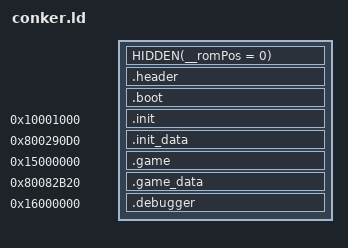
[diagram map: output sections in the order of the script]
SECTIONS
{
    HIDDEN(__romPos = 0);
    header_ROM_START = __romPos;
    header_VRAM = ADDR(.header);
    .header : AT(header_ROM_START) SUBALIGN(16)
    {
        FILL(0x00000000);
        header_DATA_START = .;
        build/asm/header.s.o(.data);
        header_DATA_END = .;
        header_DATA_SIZE = ABSOLUTE(header_DATA_END - header_DATA_START);
    }
    __romPos += SIZEOF(.header);
    header_ROM_END = __romPos;
    header_VRAM_END = .;

    boot_ROM_START = __romPos;
    boot_VRAM = ADDR(.boot);
    .boot : AT(boot_ROM_START) SUBALIGN(16)
    {
        FILL(0x00000000);
        boot_DATA_START = .;
        build/assets/boot.bin.o(.data);
        boot_DATA_END = .;
        boot_DATA_SIZE = ABSOLUTE(boot_DATA_END - boot_DATA_START);
    }
    __romPos += SIZEOF(.boot);
    boot_ROM_END = __romPos;
    boot_VRAM_END = .;

    init_ROM_START = __romPos;
    init_VRAM = ADDR(.init);
    .init 0x10001000 : AT(init_ROM_START) SUBALIGN(16)
    {
        FILL(0x00000000);
        init_TEXT_START = .;
        build/asm/entrypoint.s.o(.text);
        build/src/init_1050.c.o(.text);
        build/src/init_1420.c.o(.text);
        build/src/init_2070.c.o(.text);
        build/src/libultra/io/aisetnextbuf.c.o(.text);
        build/src/init_2E50.c.o(.text);
        build/src/libultra/io/pimgr.c.o(.text);
        build/src/libultra/io/sptask.c.o(.text);
        build/asm/libultra/io/vimgr.s.o(.text);
        build/src/libultra/os/createthread.c.o(.text);
        build/src/init_38C0.c.o(.text);
        build/src/init_38E0.c.o(.text);
        build/src/init_3920.c.o(.text);
        build/src/init_3930.c.o(.text);
        build/src/init_39B0.c.o(.text);
        build/src/init_39C0.c.o(.text);
        build/src/init_3BD0.c.o(.text);
        build/src/init_3C40.c.o(.text);
        build/src/init_4470.c.o(.text);
        build/src/init_49E0.c.o(.text);
        build/src/init_50A0.c.o(.text);
        build/asm/libultra/io/motor.s.o(.text);
        build/asm/init_5AB0.s.o(.text);
        build/asm/libultra/os/maptlbrdb.s.o(.text);
        build/src/init_8180.c.o(.text);
        build/src/init_8F90.c.o(.text);
        build/src/init_A420.c.o(.text);
        build/src/init_B1B0.c.o(.text);
        build/src/init_EB00.c.o(.text);
        build/src/init_11FA0.c.o(.text);
        build/src/init_12560.c.o(.text);
        build/src/libultra/audio/heap.c.o(.text);
        build/src/libultra/audio/init_128D0.c.o(.text);
        build/src/libultra/audio/n_csplayer.c.o(.text);
        build/src/libultra/audio/init_15550.c.o(.text);
        build/src/libultra/audio/init_17870.c.o(.text);
        build/src/libultra/audio/n_cspgetstate.c.o(.text);
        build/src/libultra/audio/code_17AA0.c.o(.text);
        build/src/libultra/audio/init_17AF0.c.o(.text);
        build/src/libultra/audio/init_17C00.c.o(.text);
        build/src/libultra/audio/code_17D80.c.o(.text);
        build/src/libultra/audio/init_17DF0.c.o(.text);
        build/src/libultra/audio/n_cspgettempo.c.o(.text);
        build/src/libultra/audio/init_17F10.c.o(.text);
        build/src/libultra/audio/n_csq.c.o(.text);
        build/src/libultra/audio/code_18C60.c.o(.text);
        build/src/libultra/audio/code_18CB0.c.o(.text);
        build/src/libultra/audio/init_18D00.c.o(.text);
        build/src/libultra/audio/init_18D50.c.o(.text);
        build/src/libultra/audio/n_sl.c.o(.text);
        build/src/libultra/audio/n_synthesizer.c.o(.text);
        build/src/libultra/audio/cents2ratio.c.o(.text);
        build/src/libultra/audio/init_19B50.c.o(.text);
        build/src/init_1AAE0.c.o(.text);
        build/src/init_1C060.c.o(.text);
        build/src/libultra/audio/n_synaddplayer.c.o(.text);
        build/src/libultra/audio/n_synstopvoice.c.o(.text);
        build/src/libultra/audio/n_synfreevoice.c.o(.text);
        build/src/libultra/audio/n_synsetvol.c.o(.text);
        build/src/libultra/audio/n_synsetpitch.c.o(.text);
        build/src/libultra/audio/n_synsetpitch2.c.o(.text);
        build/src/libultra/audio/n_synsetpan.c.o(.text);
        build/src/libultra/audio/init_1CBF0.c.o(.text);
        build/src/libultra/audio/init_1D900.c.o(.text);
        build/src/libultra/audio/n_cseqnextdelta.c.o(.text);
        build/src/libultra/audio/n_synallocvoice.c.o(.text);
        build/src/libultra/audio/n_synstartvoiceparam.c.o(.text);
        build/src/libultra/audio/init_1E2A0.c.o(.text);
        build/src/libultra/audio/init_1E350.c.o(.text);
        build/src/libultra/audio/init_1E400.c.o(.text);
        build/src/init_1E480.c.o(.text);
        build/src/init_1E4A0.c.o(.text);
        build/src/init_1E530.c.o(.text);
        build/src/init_1FB40.c.o(.text);
        build/src/libultra/audio/n_synsetpriority.c.o(.text);
        build/src/init_20000.c.o(.text);
        build/src/init_210C0.c.o(.text);
        build/src/init_214F0.c.o(.text);
        build/src/init_22040.c.o(.text);
        build/src/init_22460.c.o(.text);
        build/asm/libultra/libc/bzero.s.o(.text);
        build/src/libultra/os/initialize.c.o(.text);
        build/asm/libultra/os/setsr.s.o(.text);
        build/asm/libultra/os/getsr.s.o(.text);
        build/asm/libultra/os/setfpccsr.s.o(.text);
        build/asm/libultra/os/startthread.s.o(.text);
        build/asm/libultra/os/setthreadpri.s.o(.text);
        build/asm/libultra/os/invalicache.s.o(.text);
        build/asm/libultra/os/invaldcache.s.o(.text);
        build/asm/libultra/os/interrupt.s.o(.text);
        build/asm/libultra/os/stopthread.s.o(.text);
        build/asm/libultra/libc/string.s.o(.text);
        build/asm/libultra/libc/lldiv.s.o(.text);
        build/asm/libultra/libc/ldiv.s.o(.text);
        build/asm/libultra/libc/xlitob.s.o(.text);
        build/src/libultra/io/ai.c.o(.text);
        build/asm/libultra/os/virtualtophysical.s.o(.text);
        build/asm/libultra/os/recvmesg.s.o(.text);
        build/asm/libultra/os/sendmesg.s.o(.text);
        build/asm/libultra/os/piacs.s.o(.text);
        build/asm/libultra/os/createmesgqueue.s.o(.text);
        build/asm/libultra/os/seteventmesg.s.o(.text);
        build/src/libultra/os/getthreadpri.c.o(.text);
        build/asm/libultra/io/pirawdma.s.o(.text);
        build/asm/libultra/io/epirawdma.s.o(.text);
        build/asm/libultra/libc/bcopy.s.o(.text);
        build/asm/libultra/os/writebackdcache.s.o(.text);
        build/asm/libultra/io/spsetstat.s.o(.text);
        build/asm/libultra/io/spsetpc.s.o(.text);
        build/asm/libultra/io/sprawdma.s.o(.text);
        build/asm/libultra/io/sp.s.o(.text);
        build/asm/libultra/os/timerintr.s.o(.text);
        build/asm/libultra/io/vi.s.o(.text);
        build/asm/libultra/io/pigettype.s.o(.text);
        build/asm/libultra/io/viswapcontext.s.o(.text);
        build/asm/libultra/os/getcount.s.o(.text);
        build/asm/libultra/os/thread.s.o(.text);
        build/asm/libultra/io/visetmode.s.o(.text);
        build/asm/libultra/io/viswapbuf.s.o(.text);
        build/asm/libultra/os/setintmask.s.o(.text);
        build/asm/libultra/io/pidma.s.o(.text);
        build/src/libultra/io/aigetstat.c.o(.text);
        build/asm/libultra/os/settimer.s.o(.text);
        build/asm/libultra/io/sptaskyielded.s.o(.text);
        build/asm/libultra/io/sptaskyield.s.o(.text);
        build/asm/libultra/io/contreaddata.s.o(.text);
        build/asm/libultra/io/vigetcurrframebuf.s.o(.text);
        build/asm/libultra/io/vigetnextframebuf.s.o(.text);
        build/asm/libultra/io/visetevent.s.o(.text);
        build/asm/libultra/os/writebackdcacheall.s.o(.text);
        build/asm/libultra/os/gettime.s.o(.text);
        build/asm/libultra/io/pfsisplug.s.o(.text);
        build/asm/libultra/io/controller.s.o(.text);
        build/asm/libultra/io/siacs.s.o(.text);
        build/asm/libultra/io/sirawdma.s.o(.text);
        build/asm/libultra/io/contramwrite.s.o(.text);
        build/asm/libultra/io/contramread.s.o(.text);
        build/asm/libultra/io/crc.s.o(.text);
        build/asm/libultra/os/destroythread.s.o(.text);
        build/asm/libultra/io/viblack.s.o(.text);
        build/asm/libultra/io/pigetstat.s.o(.text);
        build/asm/libultra/os/unmaptlb.s.o(.text);
        build/asm/libultra/os/maptlb.s.o(.text);
        build/src/libultra/io/aisetfreq.c.o(.text);
        build/asm/libultra/gu/sqrtf.s.o(.text);
        build/asm/libultra/gu/sinf.s.o(.text);
        build/asm/libultra/io/sprawread.s.o(.text);
        build/asm/libultra/io/sprawwrite.s.o(.text);
        build/asm/libultra/io/pirawread.s.o(.text);
        build/asm/libultra/libc/__ull_rshift.s.o(.text);
        build/asm/libultra/os/sethwinterrupt.s.o(.text);
        build/asm/libultra/io/leointerrupt.s.o(.text);
        build/asm/libultra/os/probetlb.s.o(.text);
        build/asm/libultra/os/setcompare.s.o(.text);
        build/asm/libultra/os/jammesg.s.o(.text);
        build/asm/libultra/io/pigetcmdq.s.o(.text);
        build/asm/libultra/io/spgetstat.s.o(.text);
        build/asm/libultra/io/si.s.o(.text);
        build/asm/libultra/io/pfsinit.s.o(.text);
        build/asm/libultra/io/leodiskinit.s.o(.text);
        build/asm/libultra/io/contpfs.s.o(.text);
        build/asm/libultra/io/pfschecker.s.o(.text);
        . = ALIGN(., 16);
        init_TEXT_END = .;
        init_TEXT_SIZE = ABSOLUTE(init_TEXT_END - init_TEXT_START);
    }
    __romPos += SIZEOF(.init);
    __romPos = ALIGN(__romPos, 16);
    . = ALIGN(., 16);
    init_ROM_END = __romPos;
    init_VRAM_END = .;

    init_data_ROM_START = __romPos;
    init_data_VRAM = ADDR(.init_data);
    .init_data 0x800290D0 : AT(init_data_ROM_START) SUBALIGN(16)
    {
        FILL(0x00000000);
        init_data_DATA_START = .;
        build/asm/data/290D0.data.s.o(.data);
        . = ALIGN(., 16);
        init_data_DATA_END = .;
        init_data_DATA_SIZE = ABSOLUTE(init_data_DATA_END - init_data_DATA_START);
        init_data_RODATA_START = .;
        build/asm/data/2BF20.rodata.s.o(.rodata);
        build/asm/data/2C080.rodata.s.o(.rodata);
        build/asm/data/2C0A0.rodata.s.o(.rodata);
        build/asm/data/2C0C0.rodata.s.o(.rodata);
        build/asm/data/2C120.rodata.s.o(.rodata);
        build/asm/data/2C1B0.rodata.s.o(.rodata);
        build/asm/data/2C200.rodata.s.o(.rodata);
        build/asm/data/2C240.rodata.s.o(.rodata);
        build/asm/data/2C250.rodata.s.o(.rodata);
        build/src/libultra/audio/init_128D0.c.o(.rodata);
        build/asm/data/2C460.rodata.s.o(.rodata);
        build/asm/data/2C6B0.rodata.s.o(.rodata);
        build/asm/data/2C750.rodata.s.o(.rodata);
        build/src/libultra/audio/cents2ratio.c.o(.rodata);
        build/asm/data/2C770.rodata.s.o(.rodata);
        build/src/libultra/audio/init_1D900.c.o(.rodata);
        build/asm/data/2C7A0.rodata.s.o(.rodata);
        build/asm/data/2C820.rodata.s.o(.rodata);
        build/asm/data/2C830.rodata.s.o(.rodata);
        build/asm/data/2C850.rodata.s.o(.rodata);
        build/asm/data/2C920.rodata.s.o(.rodata);
        build/asm/data/2C960.rodata.s.o(.rodata);
        . = ALIGN(., 16);
        init_data_RODATA_END = .;
        init_data_RODATA_SIZE = ABSOLUTE(init_data_RODATA_END - init_data_RODATA_START);
    }
    __romPos += SIZEOF(.init_data);
    __romPos = ALIGN(__romPos, 16);
    . = ALIGN(., 16);
    init_data_ROM_END = __romPos;
    init_data_VRAM_END = .;

    game_ROM_START = __romPos;
    game_VRAM = ADDR(.game);
    .game 0x15000000 : AT(game_ROM_START) SUBALIGN(16)
    {
        FILL(0x00000000);
        game_TEXT_START = .;
        build/src/game_2D4B0.c.o(.text);
        build/src/game_2DDF0.c.o(.text);
        build/src/game_2DF70.c.o(.text);
        build/src/game_305D0.c.o(.text);
        build/src/game_30E90.c.o(.text);
        build/src/game_32200.c.o(.text);
        build/src/game/done/game_322B0.c.o(.text);
        build/src/game/done/game_323B0.c.o(.text);
        build/src/game/done/game_323E0.c.o(.text);
        build/src/game_32490.c.o(.text);
        build/src/game/done/game_32720.c.o(.text);
        build/src/game_32740.c.o(.text);
        build/src/game/done/game_32F10.c.o(.text);
        build/src/game/done/game_32F60.c.o(.text);
        build/src/game/done/game_32FB0.c.o(.text);
        build/src/game/done/game_32FC0.c.o(.text);
        build/src/game/done/game_33000.c.o(.text);
        build/src/game/done/game_33010.c.o(.text);
        build/src/game/done/game_33020.c.o(.text);
        build/src/game/done/game_33080.c.o(.text);
        build/src/game/done/game_330E0.c.o(.text);
        build/src/game/done/game_33130.c.o(.text);
        build/src/game/done/game_331B0.c.o(.text);
        build/src/game/done/game_33210.c.o(.text);
        build/src/game/done/game_33260.c.o(.text);
        build/src/game/done/game_332E0.c.o(.text);
        build/src/game/done/game_33320.c.o(.text);
        build/src/game/done/game_33390.c.o(.text);
        build/src/game/done/game_333D0.c.o(.text);
        build/src/game/done/game_33410.c.o(.text);
        build/src/game/done/game_33450.c.o(.text);
        build/src/game/done/game_33460.c.o(.text);
        build/src/game/done/game_334C0.c.o(.text);
        build/src/game/done/game_33620.c.o(.text);
        build/src/game_33660.c.o(.text);
        build/src/game_33990.c.o(.text);
        build/src/game/entrypoint.c.o(.text);
        build/src/game/done/game_34ED0.c.o(.text);
        build/src/game_34F20.c.o(.text);
        build/src/game_357F0.c.o(.text);
        build/src/game/done/game_35CF0.c.o(.text);
        build/src/game_35D20.c.o(.text);
        build/src/game/done/game_35E80.c.o(.text);
        build/src/game/done/game_35EC0.c.o(.text);
        build/src/game/done/game_36040.c.o(.text);
        build/src/game_360A0.c.o(.text);
        build/src/game/done/game_36280.c.o(.text);
        build/src/game_362B0.c.o(.text);
        build/src/game/done/game_36600.c.o(.text);
        build/src/game_36680.c.o(.text);
        build/src/game/done/game_39690.c.o(.text);
        build/src/game_39750.c.o(.text);
        build/src/game_3B920.c.o(.text);
        build/src/game_3BA70.c.o(.text);
        build/src/game/done/game_3BFD0.c.o(.text);
        build/src/game/done/game_3BFE0.c.o(.text);
        build/src/game/done/game_3C230.c.o(.text);
        build/src/game/done/game_3C3D0.c.o(.text);
        build/src/game/done/game_3C6C0.c.o(.text);
        build/asm/3C740.s.o(.text);
        build/asm/3CE80.s.o(.text);
        build/asm/3D2E0.s.o(.text);
        build/src/game_3D5C0.c.o(.text);
        build/src/game/done/game_3D6F0.c.o(.text);
        build/src/game/done/game_3D770.c.o(.text);
        build/src/game/done/game_3D780.c.o(.text);
        build/src/game_3D9A0.c.o(.text);
        build/src/game/done/game_3DB30.c.o(.text);
        build/src/game/done/game_3DB50.c.o(.text);
        build/src/game/done/game_3DB60.c.o(.text);
        build/src/game/done/game_3DB80.c.o(.text);
        build/src/game_3DC30.c.o(.text);
        build/src/game_3DF10.c.o(.text);
        build/src/game/done/game_3E460.c.o(.text);
        build/src/game/done/game_3E5A0.c.o(.text);
        build/src/game/done/game_3E620.c.o(.text);
        build/src/game/done/game_3E7E0.c.o(.text);
        build/src/game/done/game_3E810.c.o(.text);
        build/src/game_3E890.c.o(.text);
        build/src/game/done/game_3EFB0.c.o(.text);
        build/src/game/done/game_3F0F0.c.o(.text);
        build/src/game/done/game_3F120.c.o(.text);
        build/src/game_3F1F0.c.o(.text);
        build/src/game/done/game_3F3D0.c.o(.text);
        build/src/game/done/game_3F450.c.o(.text);
        build/src/game/done/game_3F4D0.c.o(.text);
        build/src/game/done/game_3F560.c.o(.text);
        build/src/game_3F670.c.o(.text);
        build/src/game_3F820.c.o(.text);
        build/src/game/done/game_3FBD0.c.o(.text);
        build/src/game/done/game_3FC20.c.o(.text);
        build/src/game/done/game_3FC30.c.o(.text);
        build/asm/3FC60.s.o(.text);
        build/src/game_40490.c.o(.text);
        build/asm/42DC0.s.o(.text);
        build/asm/43330.s.o(.text);
        build/src/game_433F0.c.o(.text);
        build/src/game_43620.c.o(.text);
        build/src/game/done/game_43760.c.o(.text);
        build/src/game/done/game_43820.c.o(.text);
        build/asm/43880.s.o(.text);
        build/src/game_439B0.c.o(.text);
        build/src/game/done/game_43B20.c.o(.text);
        build/asm/43D00.s.o(.text);
        build/src/game_447B0.c.o(.text);
        build/src/game_44A90.c.o(.text);
        build/src/game_44C40.c.o(.text);
        build/asm/45880.s.o(.text);
        build/src/game_45B80.c.o(.text);
        build/src/game_476D0.c.o(.text);
        build/asm/487D0.s.o(.text);
        build/asm/48FD0.s.o(.text);
        build/asm/49BE0.s.o(.text);
        build/src/game/done/game_49D10.c.o(.text);
        build/src/game/done/game_49D20.c.o(.text);
        build/asm/49D30.s.o(.text);
        build/asm/50D20.s.o(.text);
        build/asm/50D80.s.o(.text);
        build/src/game_57FA0.c.o(.text);
        build/asm/58F80.s.o(.text);
        build/asm/5D2C0.s.o(.text);
        build/asm/61490.s.o(.text);
        build/asm/61D10.s.o(.text);
        build/asm/637C0.s.o(.text);
        build/asm/63A20.s.o(.text);
        build/asm/64120.s.o(.text);
        build/asm/68C70.s.o(.text);
        build/asm/6A3D0.s.o(.text);
        build/asm/6B280.s.o(.text);
        build/asm/6B320.s.o(.text);
        build/asm/6C960.s.o(.text);
        build/asm/6CCB0.s.o(.text);
        build/asm/6CEA0.s.o(.text);
        build/src/game_6D800.c.o(.text);
        build/src/game_6E240.c.o(.text);
        build/asm/6E770.s.o(.text);
        build/src/game_70200.c.o(.text);
        build/src/game_71240.c.o(.text);
        build/src/game_71770.c.o(.text);
        build/asm/71820.s.o(.text);
        build/src/libultra/gu/cosf.c.o(.text);
        build/src/libultra/gu/sinf.c.o(.text);
        build/src/libultra/gu/guPerspectiveF.c.o(.text);
        build/src/libultra/gu/guRotateF.c.o(.text);
        build/src/game/done/game_75810.c.o(.text);
        build/src/game/done/game_75950.c.o(.text);
        build/src/game/done/game_75A90.c.o(.text);
        build/src/game/done/game_75BD0.c.o(.text);
        build/src/game_75C90.c.o(.text);
        build/src/game_75E60.c.o(.text);
        build/src/game_75FC0.c.o(.text);
        build/src/game_76710.c.o(.text);
        build/src/game/done/game_768F0.c.o(.text);
        build/asm/76A60.s.o(.text);
        build/asm/76C90.s.o(.text);
        build/asm/76E50.s.o(.text);
        build/asm/770F0.s.o(.text);
        build/asm/77760.s.o(.text);
        build/asm/778B0.s.o(.text);
        build/src/game/done/game_77A90.c.o(.text);
        build/src/game_77AD0.c.o(.text);
        build/src/game_83300.c.o(.text);
        build/asm/90840.s.o(.text);
        build/asm/97AA0.s.o(.text);
        build/src/game_981E0.c.o(.text);
        build/src/game_A28B0.c.o(.text);
        build/asm/A9260.s.o(.text);
        build/src/game_A9D90.c.o(.text);
        build/asm/AB760.s.o(.text);
        build/asm/AC030.s.o(.text);
        build/asm/AD6B0.s.o(.text);
        build/asm/AD9B0.s.o(.text);
        build/asm/AE1D0.s.o(.text);
        build/asm/AEB40.s.o(.text);
        build/asm/B21B0.s.o(.text);
        build/asm/B3020.s.o(.text);
        build/src/game_BC430.c.o(.text);
        build/src/game_BC510.c.o(.text);
        build/asm/C1D70.s.o(.text);
        build/asm/C3E20.s.o(.text);
        build/asm/C4DC0.s.o(.text);
        build/src/game_C8950.c.o(.text);
        build/asm/C98F0.s.o(.text);
        build/asm/C9EC0.s.o(.text);
        build/src/game_CB1C0.c.o(.text);
        build/asm/CB3D0.s.o(.text);
        build/asm/CBAF0.s.o(.text);
        build/asm/CBDB0.s.o(.text);
        build/asm/CCD00.s.o(.text);
        build/asm/CD5A0.s.o(.text);
        build/asm/CD860.s.o(.text);
        build/asm/CDE80.s.o(.text);
        build/asm/D0F20.s.o(.text);
        build/asm/D2570.s.o(.text);
        build/asm/D3040.s.o(.text);
        build/asm/D3D10.s.o(.text);
        build/asm/D4450.s.o(.text);
        build/src/game_D4C20.c.o(.text);
        build/src/libultra/gu/guMtxF2L.c.o(.text);
        build/asm/D4E10.s.o(.text);
        build/src/game_D5030.c.o(.text);
        build/src/libultra/gu/guMtxIdentF.c.o(.text);
        build/asm/D50C0.s.o(.text);
        build/src/game_D5160.c.o(.text);
        build/src/game_D51B0.c.o(.text);
        build/src/game_D5250.c.o(.text);
        build/asm/D52A0.s.o(.text);
        build/src/game_D5500.c.o(.text);
        build/asm/D5650.s.o(.text);
        build/asm/D70F0.s.o(.text);
        build/asm/D7980.s.o(.text);
        build/asm/D86A0.s.o(.text);
        build/asm/DAC20.s.o(.text);
        build/asm/DAC30.s.o(.text);
        build/asm/DAD60.s.o(.text);
        build/asm/DADB0.s.o(.text);
        build/asm/DAE10.s.o(.text);
        build/src/game_DAE50.c.o(.text);
        build/asm/DAFA0.s.o(.text);
        build/src/game_DBA60.c.o(.text);
        build/asm/DC360.s.o(.text);
        build/asm/DC6B0.s.o(.text);
        build/asm/DDB60.s.o(.text);
        build/asm/DE5A0.s.o(.text);
        build/asm/DF260.s.o(.text);
        build/asm/DF930.s.o(.text);
        build/asm/DFBF0.s.o(.text);
        build/asm/E0F60.s.o(.text);
        build/asm/E1280.s.o(.text);
        build/asm/E2880.s.o(.text);
        build/asm/E2DA0.s.o(.text);
        build/asm/E3C90.s.o(.text);
        build/asm/E4070.s.o(.text);
        build/asm/E5E90.s.o(.text);
        build/asm/E7380.s.o(.text);
        build/asm/E7970.s.o(.text);
        build/asm/E8090.s.o(.text);
        build/asm/E8BB0.s.o(.text);
        build/asm/E8C10.s.o(.text);
        build/asm/EB020.s.o(.text);
        build/asm/EB340.s.o(.text);
        build/asm/EBD00.s.o(.text);
        build/asm/EBE60.s.o(.text);
        build/asm/EC420.s.o(.text);
        build/asm/EDE60.s.o(.text);
        build/asm/EE710.s.o(.text);
        build/asm/EEB10.s.o(.text);
        build/asm/EEE70.s.o(.text);
        build/src/game_EF410.c.o(.text);
        build/asm/F15D0.s.o(.text);
        build/src/game/done/game_F20A0.c.o(.text);
        build/asm/F21D0.s.o(.text);
        build/asm/F2820.s.o(.text);
        build/asm/F3270.s.o(.text);
        build/asm/F3BA0.s.o(.text);
        build/asm/F44D0.s.o(.text);
        build/asm/F4800.s.o(.text);
        build/asm/F4890.s.o(.text);
        build/asm/F4B20.s.o(.text);
        build/asm/F4C20.s.o(.text);
        build/asm/F4D20.s.o(.text);
        build/asm/F52B0.s.o(.text);
        build/asm/F5800.s.o(.text);
        build/asm/F8590.s.o(.text);
        build/asm/F9430.s.o(.text);
        build/asm/FA240.s.o(.text);
        build/asm/FA360.s.o(.text);
        build/asm/FB060.s.o(.text);
        build/asm/FB600.s.o(.text);
        build/src/game/done/game_FC3C0.c.o(.text);
        build/asm/FC410.s.o(.text);
        build/asm/FC550.s.o(.text);
        build/asm/FC5F0.s.o(.text);
        build/asm/FDB00.s.o(.text);
        build/asm/FDBE0.s.o(.text);
        build/asm/FDD70.s.o(.text);
        build/asm/FE850.s.o(.text);
        build/asm/FE9E0.s.o(.text);
        build/asm/FECC0.s.o(.text);
        build/asm/FEFF0.s.o(.text);
        build/asm/FF0E0.s.o(.text);
        build/asm/FF5C0.s.o(.text);
        build/asm/FF900.s.o(.text);
        build/asm/FFBA0.s.o(.text);
        build/asm/100810.s.o(.text);
        build/asm/1028F0.s.o(.text);
        build/asm/1045D0.s.o(.text);
        build/asm/1048D0.s.o(.text);
        build/asm/105760.s.o(.text);
        build/asm/105FC0.s.o(.text);
        build/asm/108320.s.o(.text);
        build/asm/108E90.s.o(.text);
        build/src/game/done/game_10B7C0.c.o(.text);
        build/asm/10B7D0.s.o(.text);
        build/src/game/done/game_10C140.c.o(.text);
        build/asm/10C170.s.o(.text);
        build/asm/10CCD0.s.o(.text);
        build/asm/10CD70.s.o(.text);
        build/asm/10DD20.s.o(.text);
        build/asm/10E240.s.o(.text);
        build/asm/10EA20.s.o(.text);
        build/src/game/done/game_10ECB0.c.o(.text);
        build/asm/10ED10.s.o(.text);
        build/asm/10EF60.s.o(.text);
        build/asm/1104D0.s.o(.text);
        build/asm/111670.s.o(.text);
        build/asm/112F90.s.o(.text);
        build/asm/113480.s.o(.text);
        build/asm/113D60.s.o(.text);
        build/asm/116D40.s.o(.text);
        build/asm/117490.s.o(.text);
        build/asm/118400.s.o(.text);
        build/asm/118670.s.o(.text);
        build/asm/1188E0.s.o(.text);
        build/asm/119370.s.o(.text);
        build/src/game/done/game_119960.c.o(.text);
        build/asm/1199D0.s.o(.text);
        build/asm/11A680.s.o(.text);
        build/asm/11C2B0.s.o(.text);
        build/asm/11F780.s.o(.text);
        build/asm/11FF10.s.o(.text);
        build/asm/121A20.s.o(.text);
        build/src/game/done/game_122650.c.o(.text);
        build/asm/122760.s.o(.text);
        build/asm/1227F0.s.o(.text);
        build/asm/1228D0.s.o(.text);
        build/src/game_123FB0.c.o(.text);
        build/asm/124260.s.o(.text);
        build/asm/124920.s.o(.text);
        build/asm/126ED0.s.o(.text);
        build/asm/126F60.s.o(.text);
        build/asm/128970.s.o(.text);
        build/asm/128D70.s.o(.text);
        build/src/game/done/game_129EB0.c.o(.text);
        build/asm/129EE0.s.o(.text);
        build/asm/12B1C0.s.o(.text);
        build/asm/12B250.s.o(.text);
        build/asm/12B7D0.s.o(.text);
        build/asm/12BD10.s.o(.text);
        build/asm/12C1E0.s.o(.text);
        build/asm/12D630.s.o(.text);
        build/src/game/done/game_12D7E0.c.o(.text);
        build/asm/12D7F0.s.o(.text);
        build/asm/12DAB0.s.o(.text);
        build/asm/12FDD0.s.o(.text);
        build/asm/1308E0.s.o(.text);
        build/asm/130B40.s.o(.text);
        build/src/game_130CB0.c.o(.text);
        build/asm/1312F0.s.o(.text);
        build/asm/131620.s.o(.text);
        build/asm/1319D0.s.o(.text);
        build/asm/131A90.s.o(.text);
        build/src/game_131F30.c.o(.text);
        build/asm/133190.s.o(.text);
        build/asm/135490.s.o(.text);
        build/asm/1355D0.s.o(.text);
        build/asm/135780.s.o(.text);
        build/asm/135D00.s.o(.text);
        build/asm/1368C0.s.o(.text);
        build/asm/137DE0.s.o(.text);
        build/asm/137ED0.s.o(.text);
        build/asm/138520.s.o(.text);
        build/asm/139FC0.s.o(.text);
        build/asm/13AE20.s.o(.text);
        build/asm/13BB20.s.o(.text);
        build/asm/13D350.s.o(.text);
        build/asm/142560.s.o(.text);
        build/asm/14CE30.s.o(.text);
        build/src/game/done/game_14D0D0.c.o(.text);
        build/asm/14D110.s.o(.text);
        build/asm/14EE80.s.o(.text);
        build/asm/14F130.s.o(.text);
        build/asm/14F580.s.o(.text);
        build/asm/14F8F0.s.o(.text);
        build/src/game_14FF90.c.o(.text);
        build/asm/155C90.s.o(.text);
        build/asm/156160.s.o(.text);
        build/asm/1570E0.s.o(.text);
        build/asm/157840.s.o(.text);
        build/asm/159940.s.o(.text);
        build/src/game/done/game_15A830.c.o(.text);
        build/asm/15A840.s.o(.text);
        build/asm/15AA10.s.o(.text);
        build/asm/15ABA0.s.o(.text);
        build/src/game_15B200.c.o(.text);
        build/asm/15B5F0.s.o(.text);
        build/asm/15B960.s.o(.text);
        build/asm/15BAA0.s.o(.text);
        build/asm/15BD90.s.o(.text);
        build/asm/15D6E0.s.o(.text);
        build/asm/15D730.s.o(.text);
        build/asm/15F680.s.o(.text);
        build/src/game_161520.c.o(.text);
        build/src/game_168A90.c.o(.text);
        build/src/game_169510.c.o(.text);
        build/src/game_16DC80.c.o(.text);
        build/src/game_16EE20.c.o(.text);
        build/asm/173D40.s.o(.text);
        build/asm/174BF0.s.o(.text);
        build/asm/175250.s.o(.text);
        build/src/game/done/game_1765E0.c.o(.text);
        build/asm/176A00.s.o(.text);
        build/asm/179F30.s.o(.text);
        build/asm/17CAF0.s.o(.text);
        build/asm/182C30.s.o(.text);
        build/asm/183640.s.o(.text);
        build/asm/185560.s.o(.text);
        build/asm/188440.s.o(.text);
        build/asm/188F90.s.o(.text);
        build/src/game_1897A0.c.o(.text);
        build/asm/18A8F0.s.o(.text);
        build/asm/18D250.s.o(.text);
        build/src/game_18D770.c.o(.text);
        build/asm/191C30.s.o(.text);
        build/asm/193130.s.o(.text);
        build/src/game/done/game_193420.c.o(.text);
        build/asm/193430.s.o(.text);
        build/asm/193E50.s.o(.text);
        build/src/game_1944C0.c.o(.text);
        build/asm/196DB0.s.o(.text);
        build/asm/197120.s.o(.text);
        build/asm/197C20.s.o(.text);
        build/asm/19A8B0.s.o(.text);
        build/asm/19E040.s.o(.text);
        build/asm/19F150.s.o(.text);
        build/asm/1A0100.s.o(.text);
        build/asm/1A0420.s.o(.text);
        build/asm/1A0790.s.o(.text);
        build/asm/1A0E60.s.o(.text);
        build/asm/1A11B0.s.o(.text);
        build/asm/1A1B40.s.o(.text);
        build/asm/1A1E50.s.o(.text);
        build/asm/1A20A0.s.o(.text);
        build/asm/1A48C0.s.o(.text);
        build/asm/1A5440.s.o(.text);
        build/src/game/done/game_1A6300.c.o(.text);
        build/asm/1A6360.s.o(.text);
        build/asm/1A7260.s.o(.text);
        build/asm/1A8060.s.o(.text);
        build/asm/1A89B0.s.o(.text);
        build/asm/1AB530.s.o(.text);
        build/asm/1AC2F0.s.o(.text);
        build/asm/1AFC80.s.o(.text);
        build/asm/1B0740.s.o(.text);
        build/asm/1B1600.s.o(.text);
        build/asm/1B5370.s.o(.text);
        build/asm/1B5CC0.s.o(.text);
        build/asm/1B6DB0.s.o(.text);
        build/asm/1B74A0.s.o(.text);
        build/asm/1B7870.s.o(.text);
        build/asm/1B7EC0.s.o(.text);
        build/asm/1B81D0.s.o(.text);
        build/asm/1B8B60.s.o(.text);
        build/asm/1B8F40.s.o(.text);
        build/asm/1B9DB0.s.o(.text);
        build/asm/1B9F30.s.o(.text);
        build/asm/1BA1D0.s.o(.text);
        build/asm/1BF090.s.o(.text);
        build/src/game_1BFC70.c.o(.text);
        build/asm/1BFCB0.s.o(.text);
        build/asm/1BFDD0.s.o(.text);
        build/asm/1C0840.s.o(.text);
        build/asm/1C0B10.s.o(.text);
        build/asm/1C1150.s.o(.text);
        build/asm/1C2C60.s.o(.text);
        build/asm/1CA420.s.o(.text);
        build/asm/1CBE20.s.o(.text);
        build/src/game/done/game_1CC420.c.o(.text);
        build/asm/1CC440.s.o(.text);
        build/asm/1D0840.s.o(.text);
        build/asm/1D2B10.s.o(.text);
        build/asm/1D43B0.s.o(.text);
        build/asm/1D4E00.s.o(.text);
        build/asm/1D6E80.s.o(.text);
        build/asm/1D92F0.s.o(.text);
        build/asm/1DCA70.s.o(.text);
        build/asm/1DD500.s.o(.text);
        build/asm/1DF510.s.o(.text);
        build/asm/1E0560.s.o(.text);
        build/asm/1E2180.s.o(.text);
        build/asm/1E26F0.s.o(.text);
        build/asm/1E3050.s.o(.text);
        build/asm/1E30A0.s.o(.text);
        build/asm/1E34C0.s.o(.text);
        build/asm/1E37D0.s.o(.text);
        build/asm/1E58B0.s.o(.text);
        build/asm/1E5FF0.s.o(.text);
        build/asm/1E6260.s.o(.text);
        build/asm/1E6B40.s.o(.text);
        build/asm/1E73B0.s.o(.text);
        build/asm/1ED0F0.s.o(.text);
        build/asm/1EF500.s.o(.text);
        build/asm/1F2730.s.o(.text);
        build/asm/1F3780.s.o(.text);
        build/asm/1F4650.s.o(.text);
        build/asm/1FA770.s.o(.text);
        build/asm/1FFB70.s.o(.text);
        build/src/game_1FFF60.c.o(.text);
        build/asm/200930.s.o(.text);
        build/asm/203340.s.o(.text);
        build/asm/203E20.s.o(.text);
        build/asm/204660.s.o(.text);
        build/asm/205C90.s.o(.text);
        build/src/game_2062D0.c.o(.text);
        build/asm/209B50.s.o(.text);
        build/asm/20A290.s.o(.text);
        build/asm/20A3A0.s.o(.text);
        build/asm/20A5F0.s.o(.text);
        build/asm/20A850.s.o(.text);
        build/asm/20A910.s.o(.text);
        build/asm/20A990.s.o(.text);
        build/asm/20AE20.s.o(.text);
        build/asm/215960.s.o(.text);
        build/asm/21C4F0.s.o(.text);
        build/asm/21C540.s.o(.text);
        build/asm/libultra/io/pfsinit2.s.o(.text);
        build/asm/21CAC0.s.o(.text);
        build/asm/21CAF0.s.o(.text);
        build/asm/21CCB0.s.o(.text);
        build/asm/21CE70.s.o(.text);
        build/asm/libultra/io/contreaddata2.s.o(.text);
        build/asm/21D1B0.s.o(.text);
        build/asm/21D420.s.o(.text);
        build/src/libultra/gu/guNormalize.c.o(.text);
        build/src/libultra/gu/mtxcatl.c.o(.text);
        build/src/game_21D5F0.c.o(.text);
        build/asm/libultra/io/siacs2.s.o(.text);
        build/asm/libultra/io/sirawdma2.s.o(.text);
        build/asm/libultra/os/gettime2.s.o(.text);
        build/asm/libultra/io/contpfs2.s.o(.text);
        build/src/libultra/io/pfschecker2.c.o(.text);
        build/src/libultra/io/pfsisplug2.c.o(.text);
        build/asm/libultra/io/contramread2.s.o(.text);
        build/asm/libultra/io/contramwrite2.s.o(.text);
        build/src/libultra/audio/game_21FC90.c.o(.text);
        build/src/game_221290.c.o(.text);
        build/asm/225D20.s.o(.text);
        build/asm/2270A0.s.o(.text);
        . = ALIGN(., 16);
        game_TEXT_END = .;
        game_TEXT_SIZE = ABSOLUTE(game_TEXT_END - game_TEXT_START);
    }
    __romPos += SIZEOF(.game);
    __romPos = ALIGN(__romPos, 16);
    . = ALIGN(., 16);
    game_ROM_END = __romPos;
    game_VRAM_END = .;

    game_data_ROM_START = __romPos;
    game_data_VRAM = ADDR(.game_data);
    .game_data 0x80082B20 : AT(game_data_ROM_START) SUBALIGN(16)
    {
        FILL(0x00000000);
        game_data_DATA_START = .;
        build/asm/data/2275E0.data.s.o(.data);
        . = ALIGN(., 16);
        game_data_DATA_END = .;
        game_data_DATA_SIZE = ABSOLUTE(game_data_DATA_END - game_data_DATA_START);
        game_data_RODATA_START = .;
        build/asm/data/22A980.rodata.s.o(.rodata);
        build/asm/data/22AA90.rodata.s.o(.rodata);
        build/asm/data/22AAB0.rodata.s.o(.rodata);
        build/asm/data/22AAC0.rodata.s.o(.rodata);
        build/asm/data/22ABC0.rodata.s.o(.rodata);
        build/asm/data/22ABD0.rodata.s.o(.rodata);
        build/asm/data/22AC10.rodata.s.o(.rodata);
        build/asm/data/22B1F0.rodata.s.o(.rodata);
        build/asm/data/22B560.rodata.s.o(.rodata);
        build/asm/data/22B660.rodata.s.o(.rodata);
        build/asm/data/22B720.rodata.s.o(.rodata);
        build/asm/data/22BD00.rodata.s.o(.rodata);
        build/asm/data/22BD20.rodata.s.o(.rodata);
        build/asm/data/22BD40.rodata.s.o(.rodata);
        build/asm/data/22BD50.rodata.s.o(.rodata);
        build/asm/data/22BD70.rodata.s.o(.rodata);
        build/asm/data/22BD90.rodata.s.o(.rodata);
        build/asm/data/22BDE0.rodata.s.o(.rodata);
        build/asm/data/22BE40.rodata.s.o(.rodata);
        build/asm/data/22BE50.rodata.s.o(.rodata);
        build/asm/data/22BE70.rodata.s.o(.rodata);
        build/asm/data/22BE90.rodata.s.o(.rodata);
        build/asm/data/22BED0.rodata.s.o(.rodata);
        build/asm/data/22BEF0.rodata.s.o(.rodata);
        build/asm/data/22D000.rodata.s.o(.rodata);
        build/asm/data/22D040.rodata.s.o(.rodata);
        build/asm/data/22D070.rodata.s.o(.rodata);
        build/asm/data/22D1A0.rodata.s.o(.rodata);
        build/asm/data/22D1B0.rodata.s.o(.rodata);
        build/asm/data/22D1C0.rodata.s.o(.rodata);
        build/asm/data/22D1D0.rodata.s.o(.rodata);
        build/asm/data/22D1E0.rodata.s.o(.rodata);
        build/asm/data/22D1F0.rodata.s.o(.rodata);
        build/asm/data/22D210.rodata.s.o(.rodata);
        build/asm/data/22D220.rodata.s.o(.rodata);
        build/asm/data/22D250.rodata.s.o(.rodata);
        build/asm/data/22D2A0.rodata.s.o(.rodata);
        build/asm/data/22D2C0.rodata.s.o(.rodata);
        build/asm/data/22D2D0.rodata.s.o(.rodata);
        build/asm/data/22D2E0.rodata.s.o(.rodata);
        build/asm/data/22D330.rodata.s.o(.rodata);
        build/asm/data/22D350.rodata.s.o(.rodata);
        build/asm/data/22D380.rodata.s.o(.rodata);
        build/asm/data/22D3C0.rodata.s.o(.rodata);
        build/asm/data/22D3D0.rodata.s.o(.rodata);
        build/asm/data/22D3F0.rodata.s.o(.rodata);
        build/asm/data/22D400.rodata.s.o(.rodata);
        build/asm/data/22D410.rodata.s.o(.rodata);
        build/asm/data/22D420.rodata.s.o(.rodata);
        build/asm/data/22D440.rodata.s.o(.rodata);
        build/asm/data/22D450.rodata.s.o(.rodata);
        build/asm/data/22D460.rodata.s.o(.rodata);
        build/asm/data/22D480.rodata.s.o(.rodata);
        build/asm/data/22D4D0.rodata.s.o(.rodata);
        build/asm/data/22D4E0.rodata.s.o(.rodata);
        build/asm/data/22D550.rodata.s.o(.rodata);
        build/asm/data/22D560.rodata.s.o(.rodata);
        build/asm/data/22D5C0.rodata.s.o(.rodata);
        build/asm/data/22D5E0.rodata.s.o(.rodata);
        build/asm/data/22D600.rodata.s.o(.rodata);
        build/asm/data/22D610.rodata.s.o(.rodata);
        build/asm/data/22D620.rodata.s.o(.rodata);
        build/asm/data/22D640.rodata.s.o(.rodata);
        build/asm/data/22D650.rodata.s.o(.rodata);
        build/asm/data/22D660.rodata.s.o(.rodata);
        build/asm/data/22D670.rodata.s.o(.rodata);
        build/asm/data/22D680.rodata.s.o(.rodata);
        build/asm/data/22D690.rodata.s.o(.rodata);
        build/asm/data/22D6C0.rodata.s.o(.rodata);
        build/asm/data/22D6D0.rodata.s.o(.rodata);
        build/asm/data/22D710.rodata.s.o(.rodata);
        build/asm/data/22DB80.rodata.s.o(.rodata);
        build/asm/data/22DBE0.rodata.s.o(.rodata);
        build/asm/data/22DBF0.rodata.s.o(.rodata);
        build/asm/data/22DD00.rodata.s.o(.rodata);
        build/asm/data/22DD20.rodata.s.o(.rodata);
        build/asm/data/22DDE0.rodata.s.o(.rodata);
        build/asm/data/22DF30.rodata.s.o(.rodata);
        build/asm/data/22DF70.rodata.s.o(.rodata);
        build/asm/data/22DF80.rodata.s.o(.rodata);
        build/asm/data/22DFA0.rodata.s.o(.rodata);
        build/asm/data/22DFB0.rodata.s.o(.rodata);
        build/asm/data/22DFE0.rodata.s.o(.rodata);
        build/asm/data/22E020.rodata.s.o(.rodata);
        build/asm/data/22E030.rodata.s.o(.rodata);
        build/asm/data/22E040.rodata.s.o(.rodata);
        build/asm/data/22E050.rodata.s.o(.rodata);
        build/asm/data/22E090.rodata.s.o(.rodata);
        build/asm/data/22E0F0.rodata.s.o(.rodata);
        build/asm/data/22E1F0.rodata.s.o(.rodata);
        build/asm/data/22E220.rodata.s.o(.rodata);
        build/asm/data/22E370.rodata.s.o(.rodata);
        build/asm/data/22E4E0.rodata.s.o(.rodata);
        build/asm/data/22E680.rodata.s.o(.rodata);
        build/asm/data/22E730.rodata.s.o(.rodata);
        build/asm/data/22EB40.rodata.s.o(.rodata);
        build/asm/data/22EC20.rodata.s.o(.rodata);
        build/asm/data/22EC90.rodata.s.o(.rodata);
        build/asm/data/22ECB0.rodata.s.o(.rodata);
        build/asm/data/22ECC0.rodata.s.o(.rodata);
        build/asm/data/22EEA0.rodata.s.o(.rodata);
        build/asm/data/22EF30.rodata.s.o(.rodata);
        build/asm/data/22EF80.rodata.s.o(.rodata);
        build/asm/data/22F530.rodata.s.o(.rodata);
        build/asm/data/22F650.rodata.s.o(.rodata);
        build/asm/data/22F720.rodata.s.o(.rodata);
        build/asm/data/22F730.rodata.s.o(.rodata);
        build/asm/data/22F7F0.rodata.s.o(.rodata);
        build/asm/data/22F800.rodata.s.o(.rodata);
        build/asm/data/22F820.rodata.s.o(.rodata);
        build/asm/data/22F840.rodata.s.o(.rodata);
        build/asm/data/22F850.rodata.s.o(.rodata);
        build/asm/data/22F8B0.rodata.s.o(.rodata);
        build/asm/data/22F8C0.rodata.s.o(.rodata);
        build/asm/data/22F920.rodata.s.o(.rodata);
        build/asm/data/22F9A0.rodata.s.o(.rodata);
        build/asm/data/22FA40.rodata.s.o(.rodata);
        build/asm/data/22FA90.rodata.s.o(.rodata);
        build/asm/data/22FB10.rodata.s.o(.rodata);
        build/asm/data/22FB50.rodata.s.o(.rodata);
        build/asm/data/22FB90.rodata.s.o(.rodata);
        build/asm/data/22FE50.rodata.s.o(.rodata);
        build/asm/data/22FE60.rodata.s.o(.rodata);
        build/asm/data/22FEA0.rodata.s.o(.rodata);
        build/asm/data/22FF00.rodata.s.o(.rodata);
        build/asm/data/22FF40.rodata.s.o(.rodata);
        build/asm/data/22FF90.rodata.s.o(.rodata);
        build/asm/data/231650.rodata.s.o(.rodata);
        build/asm/data/231660.rodata.s.o(.rodata);
        build/asm/data/2316E0.rodata.s.o(.rodata);
        build/asm/data/2316F0.rodata.s.o(.rodata);
        build/asm/data/231730.rodata.s.o(.rodata);
        build/asm/data/231850.rodata.s.o(.rodata);
        build/asm/data/2318E0.rodata.s.o(.rodata);
        build/asm/data/231900.rodata.s.o(.rodata);
        build/asm/data/231920.rodata.s.o(.rodata);
        build/asm/data/231970.rodata.s.o(.rodata);
        build/asm/data/2319C0.rodata.s.o(.rodata);
        build/asm/data/231AB0.rodata.s.o(.rodata);
        build/asm/data/231B10.rodata.s.o(.rodata);
        build/asm/data/231B20.rodata.s.o(.rodata);
        build/asm/data/231E80.rodata.s.o(.rodata);
        build/asm/data/231EA0.rodata.s.o(.rodata);
        build/asm/data/231FB0.rodata.s.o(.rodata);
        build/asm/data/231FE0.rodata.s.o(.rodata);
        build/asm/data/232040.rodata.s.o(.rodata);
        build/asm/data/232060.rodata.s.o(.rodata);
        build/asm/data/232090.rodata.s.o(.rodata);
        build/asm/data/2320A0.rodata.s.o(.rodata);
        build/asm/data/232150.rodata.s.o(.rodata);
        build/asm/data/233920.rodata.s.o(.rodata);
        build/asm/data/233990.rodata.s.o(.rodata);
        build/asm/data/233A00.rodata.s.o(.rodata);
        build/asm/data/233A70.rodata.s.o(.rodata);
        build/asm/data/233BC0.rodata.s.o(.rodata);
        build/asm/data/233C30.rodata.s.o(.rodata);
        build/asm/data/233CA0.rodata.s.o(.rodata);
        build/asm/data/233D10.rodata.s.o(.rodata);
        build/asm/data/233D80.rodata.s.o(.rodata);
        build/asm/data/2342A0.rodata.s.o(.rodata);
        build/asm/data/2342D0.rodata.s.o(.rodata);
        build/asm/data/234300.rodata.s.o(.rodata);
        build/asm/data/234310.rodata.s.o(.rodata);
        build/asm/data/234320.rodata.s.o(.rodata);
        build/asm/data/234330.rodata.s.o(.rodata);
        build/asm/data/234390.rodata.s.o(.rodata);
        build/asm/data/2343A0.rodata.s.o(.rodata);
        build/asm/data/2343C0.rodata.s.o(.rodata);
        build/asm/data/2343D0.rodata.s.o(.rodata);
        build/asm/data/2343F0.rodata.s.o(.rodata);
        build/asm/data/234400.rodata.s.o(.rodata);
        build/asm/data/234520.rodata.s.o(.rodata);
        build/asm/data/234530.rodata.s.o(.rodata);
        build/asm/data/2345B0.rodata.s.o(.rodata);
        build/asm/data/234600.rodata.s.o(.rodata);
        build/asm/data/234630.rodata.s.o(.rodata);
        build/asm/data/234640.rodata.s.o(.rodata);
        build/asm/data/234650.rodata.s.o(.rodata);
        build/asm/data/234660.rodata.s.o(.rodata);
        build/asm/data/234680.rodata.s.o(.rodata);
        build/asm/data/234690.rodata.s.o(.rodata);
        build/asm/data/2346D0.rodata.s.o(.rodata);
        build/asm/data/2346F0.rodata.s.o(.rodata);
        build/asm/data/234700.rodata.s.o(.rodata);
        build/asm/data/234730.rodata.s.o(.rodata);
        build/asm/data/234760.rodata.s.o(.rodata);
        build/asm/data/234780.rodata.s.o(.rodata);
        build/asm/data/234790.rodata.s.o(.rodata);
        build/asm/data/234830.rodata.s.o(.rodata);
        build/asm/data/234900.rodata.s.o(.rodata);
        build/asm/data/234A70.rodata.s.o(.rodata);
        build/asm/data/234C10.rodata.s.o(.rodata);
        build/asm/data/234CB0.rodata.s.o(.rodata);
        build/asm/data/236430.rodata.s.o(.rodata);
        build/asm/data/2365B0.rodata.s.o(.rodata);
        build/asm/data/2367E0.rodata.s.o(.rodata);
        build/asm/data/23A490.rodata.s.o(.rodata);
        build/asm/data/23A4A0.rodata.s.o(.rodata);
        build/asm/data/23A4C0.rodata.s.o(.rodata);
        build/asm/data/23A4F0.rodata.s.o(.rodata);
        build/asm/data/23A510.rodata.s.o(.rodata);
        build/asm/data/23A5D0.rodata.s.o(.rodata);
        build/asm/data/23A600.rodata.s.o(.rodata);
        build/asm/data/23A630.rodata.s.o(.rodata);
        build/asm/data/23A6A0.rodata.s.o(.rodata);
        build/asm/data/23A7A0.rodata.s.o(.rodata);
        build/asm/data/23AA60.rodata.s.o(.rodata);
        build/asm/data/23AD10.rodata.s.o(.rodata);
        build/asm/data/23ADE0.rodata.s.o(.rodata);
        build/asm/data/23AE60.rodata.s.o(.rodata);
        build/asm/data/23AF10.rodata.s.o(.rodata);
        build/asm/data/23AF80.rodata.s.o(.rodata);
        build/asm/data/23AFD0.rodata.s.o(.rodata);
        build/asm/data/23AFF0.rodata.s.o(.rodata);
        build/asm/data/23B000.rodata.s.o(.rodata);
        build/asm/data/23B010.rodata.s.o(.rodata);
        build/asm/data/23B020.rodata.s.o(.rodata);
        build/asm/data/23B030.rodata.s.o(.rodata);
        build/asm/data/23B040.rodata.s.o(.rodata);
        build/asm/data/23B370.rodata.s.o(.rodata);
        build/asm/data/23B380.rodata.s.o(.rodata);
        build/asm/data/23B390.rodata.s.o(.rodata);
        build/asm/data/23B3A0.rodata.s.o(.rodata);
        build/asm/data/23B3D0.rodata.s.o(.rodata);
        build/asm/data/23B3E0.rodata.s.o(.rodata);
        build/asm/data/23B420.rodata.s.o(.rodata);
        build/asm/data/23B480.rodata.s.o(.rodata);
        build/asm/data/23B4E0.rodata.s.o(.rodata);
        build/asm/data/23B8A0.rodata.s.o(.rodata);
        build/asm/data/23C630.rodata.s.o(.rodata);
        build/asm/data/23C800.rodata.s.o(.rodata);
        build/asm/data/23C830.rodata.s.o(.rodata);
        build/asm/data/23C840.rodata.s.o(.rodata);
        build/asm/data/23C850.rodata.s.o(.rodata);
        build/asm/data/23CB10.rodata.s.o(.rodata);
        build/asm/data/23CD10.rodata.s.o(.rodata);
        build/asm/data/23D1B0.rodata.s.o(.rodata);
        build/asm/data/23D320.rodata.s.o(.rodata);
        build/asm/data/23D3F0.rodata.s.o(.rodata);
        build/asm/data/23D420.rodata.s.o(.rodata);
        build/asm/data/23D570.rodata.s.o(.rodata);
        build/asm/data/23D650.rodata.s.o(.rodata);
        build/asm/data/23D730.rodata.s.o(.rodata);
        build/asm/data/23D830.rodata.s.o(.rodata);
        build/asm/data/23D850.rodata.s.o(.rodata);
        build/src/libultra/gu/guPerspectiveF.c.o(.rodata);
        build/src/libultra/gu/guRotateF.c.o(.rodata);
        build/src/game/done/game_75810.c.o(.rodata);
        build/src/game/done/game_75950.c.o(.rodata);
        build/asm/data/game_75C90.rodata.s.o(.rodata);
        build/asm/data/game_75FC0.rodata.s.o(.rodata);
        build/asm/data/23DB30.rodata.s.o(.rodata);
        build/asm/data/game_76710.rodata.s.o(.rodata);
        build/asm/data/23DB50.rodata.s.o(.rodata);
        build/asm/data/23DB60.rodata.s.o(.rodata);
        build/asm/data/23DB70.rodata.s.o(.rodata);
        build/asm/data/23DB80.rodata.s.o(.rodata);
        build/asm/data/23DC00.rodata.s.o(.rodata);
        build/asm/data/23E160.rodata.s.o(.rodata);
        build/asm/data/23E4D0.rodata.s.o(.rodata);
        build/asm/data/23E4F0.rodata.s.o(.rodata);
        build/asm/data/23EBE0.rodata.s.o(.rodata);
        build/asm/data/240360.rodata.s.o(.rodata);
        build/asm/data/240370.rodata.s.o(.rodata);
        build/asm/data/2405A0.rodata.s.o(.rodata);
        build/asm/data/2407D0.rodata.s.o(.rodata);
        build/asm/data/2407F0.rodata.s.o(.rodata);
        build/asm/data/2416F0.rodata.s.o(.rodata);
        build/asm/data/241890.rodata.s.o(.rodata);
        build/asm/data/2418C0.rodata.s.o(.rodata);
        build/asm/data/2418D0.rodata.s.o(.rodata);
        build/asm/data/2418E0.rodata.s.o(.rodata);
        build/asm/data/2418F0.rodata.s.o(.rodata);
        build/asm/data/241900.rodata.s.o(.rodata);
        build/asm/data/241910.rodata.s.o(.rodata);
        build/asm/data/241920.rodata.s.o(.rodata);
        build/asm/data/241930.rodata.s.o(.rodata);
        build/asm/data/241940.rodata.s.o(.rodata);
        build/asm/data/241950.rodata.s.o(.rodata);
        build/asm/data/241960.rodata.s.o(.rodata);
        build/asm/data/241970.rodata.s.o(.rodata);
        build/asm/data/241980.rodata.s.o(.rodata);
        build/asm/data/241990.rodata.s.o(.rodata);
        build/asm/data/2419B0.rodata.s.o(.rodata);
        build/asm/data/2419D0.rodata.s.o(.rodata);
        build/asm/data/2419E0.rodata.s.o(.rodata);
        build/asm/data/2419F0.rodata.s.o(.rodata);
        build/asm/data/241A10.rodata.s.o(.rodata);
        build/asm/data/241A20.rodata.s.o(.rodata);
        build/asm/data/241A50.rodata.s.o(.rodata);
        build/asm/data/241A60.rodata.s.o(.rodata);
        build/asm/data/241A70.rodata.s.o(.rodata);
        build/asm/data/241A80.rodata.s.o(.rodata);
        build/asm/data/241A90.rodata.s.o(.rodata);
        build/asm/data/241AB0.rodata.s.o(.rodata);
        build/asm/data/241AC0.rodata.s.o(.rodata);
        build/asm/data/241AD0.rodata.s.o(.rodata);
        build/asm/data/241AF0.rodata.s.o(.rodata);
        build/asm/data/241B00.rodata.s.o(.rodata);
        build/asm/data/241B10.rodata.s.o(.rodata);
        build/asm/data/241B20.rodata.s.o(.rodata);
        build/asm/data/241B40.rodata.s.o(.rodata);
        build/asm/data/241B50.rodata.s.o(.rodata);
        build/asm/data/241B60.rodata.s.o(.rodata);
        build/asm/data/241B70.rodata.s.o(.rodata);
        build/asm/data/241B80.rodata.s.o(.rodata);
        build/asm/data/241B90.rodata.s.o(.rodata);
        build/asm/data/241BA0.rodata.s.o(.rodata);
        build/asm/data/241BB0.rodata.s.o(.rodata);
        build/asm/data/241BC0.rodata.s.o(.rodata);
        build/asm/data/241BD0.rodata.s.o(.rodata);
        build/asm/data/241BE0.rodata.s.o(.rodata);
        build/asm/data/241C00.rodata.s.o(.rodata);
        build/asm/data/241C10.rodata.s.o(.rodata);
        build/asm/data/241C20.rodata.s.o(.rodata);
        build/asm/data/241C30.rodata.s.o(.rodata);
        build/asm/data/241C40.rodata.s.o(.rodata);
        build/asm/data/241C60.rodata.s.o(.rodata);
        build/asm/data/241C70.rodata.s.o(.rodata);
        build/asm/data/241C80.rodata.s.o(.rodata);
        build/asm/data/241C90.rodata.s.o(.rodata);
        build/asm/data/241CA0.rodata.s.o(.rodata);
        build/asm/data/241CB0.rodata.s.o(.rodata);
        build/asm/data/241CC0.rodata.s.o(.rodata);
        build/asm/data/241CD0.rodata.s.o(.rodata);
        build/asm/data/241CF0.rodata.s.o(.rodata);
        build/asm/data/241D00.rodata.s.o(.rodata);
        build/asm/data/241D10.rodata.s.o(.rodata);
        build/asm/data/241D20.rodata.s.o(.rodata);
        build/asm/data/241D30.rodata.s.o(.rodata);
        build/asm/data/241D40.rodata.s.o(.rodata);
        build/asm/data/241D50.rodata.s.o(.rodata);
        build/asm/data/241D70.rodata.s.o(.rodata);
        build/asm/data/241DA0.rodata.s.o(.rodata);
        build/asm/data/241DB0.rodata.s.o(.rodata);
        build/asm/data/241DC0.rodata.s.o(.rodata);
        build/asm/data/241DD0.rodata.s.o(.rodata);
        build/asm/data/241DE0.rodata.s.o(.rodata);
        build/asm/data/241DF0.rodata.s.o(.rodata);
        build/asm/data/241E10.rodata.s.o(.rodata);
        build/asm/data/241E30.rodata.s.o(.rodata);
        build/asm/data/241E40.rodata.s.o(.rodata);
        build/asm/data/241E50.rodata.s.o(.rodata);
        build/asm/data/241E60.rodata.s.o(.rodata);
        build/asm/data/241E70.rodata.s.o(.rodata);
        build/asm/data/241E80.rodata.s.o(.rodata);
        build/asm/data/241E90.rodata.s.o(.rodata);
        build/asm/data/241EA0.rodata.s.o(.rodata);
        build/asm/data/241EB0.rodata.s.o(.rodata);
        build/asm/data/241ED0.rodata.s.o(.rodata);
        build/asm/data/241EE0.rodata.s.o(.rodata);
        build/asm/data/241EF0.rodata.s.o(.rodata);
        build/asm/data/241F00.rodata.s.o(.rodata);
        build/asm/data/241F10.rodata.s.o(.rodata);
        build/asm/data/241F30.rodata.s.o(.rodata);
        build/asm/data/241F40.rodata.s.o(.rodata);
        build/asm/data/241F50.rodata.s.o(.rodata);
        build/asm/data/241F60.rodata.s.o(.rodata);
        build/asm/data/241F70.rodata.s.o(.rodata);
        build/asm/data/241F80.rodata.s.o(.rodata);
        build/asm/data/241F90.rodata.s.o(.rodata);
        build/asm/data/241FA0.rodata.s.o(.rodata);
        build/asm/data/241FB0.rodata.s.o(.rodata);
        build/asm/data/241FD0.rodata.s.o(.rodata);
        build/asm/data/241FE0.rodata.s.o(.rodata);
        build/asm/data/241FF0.rodata.s.o(.rodata);
        build/asm/data/242000.rodata.s.o(.rodata);
        build/asm/data/242010.rodata.s.o(.rodata);
        build/asm/data/242020.rodata.s.o(.rodata);
        build/asm/data/242030.rodata.s.o(.rodata);
        build/asm/data/242040.rodata.s.o(.rodata);
        build/asm/data/242060.rodata.s.o(.rodata);
        build/asm/data/242070.rodata.s.o(.rodata);
        build/asm/data/242080.rodata.s.o(.rodata);
        build/asm/data/242090.rodata.s.o(.rodata);
        build/asm/data/2420A0.rodata.s.o(.rodata);
        build/asm/data/2420B0.rodata.s.o(.rodata);
        build/asm/data/2420C0.rodata.s.o(.rodata);
        build/asm/data/2420D0.rodata.s.o(.rodata);
        build/asm/data/2420E0.rodata.s.o(.rodata);
        build/asm/data/2420F0.rodata.s.o(.rodata);
        build/asm/data/242100.rodata.s.o(.rodata);
        build/asm/data/242110.rodata.s.o(.rodata);
        build/asm/data/242120.rodata.s.o(.rodata);
        build/asm/data/242130.rodata.s.o(.rodata);
        build/asm/data/242140.rodata.s.o(.rodata);
        build/asm/data/242150.rodata.s.o(.rodata);
        build/asm/data/242160.rodata.s.o(.rodata);
        build/asm/data/242170.rodata.s.o(.rodata);
        build/asm/data/242180.rodata.s.o(.rodata);
        build/asm/data/242190.rodata.s.o(.rodata);
        build/asm/data/2421A0.rodata.s.o(.rodata);
        build/asm/data/2421B0.rodata.s.o(.rodata);
        build/asm/data/2421C0.rodata.s.o(.rodata);
        build/asm/data/2421D0.rodata.s.o(.rodata);
        build/asm/data/2421E0.rodata.s.o(.rodata);
        build/asm/data/2421F0.rodata.s.o(.rodata);
        build/asm/data/242200.rodata.s.o(.rodata);
        build/asm/data/242220.rodata.s.o(.rodata);
        build/asm/data/242230.rodata.s.o(.rodata);
        build/asm/data/242240.rodata.s.o(.rodata);
        build/asm/data/242250.rodata.s.o(.rodata);
        build/asm/data/242260.rodata.s.o(.rodata);
        build/asm/data/242280.rodata.s.o(.rodata);
        build/asm/data/2422A0.rodata.s.o(.rodata);
        build/asm/data/2422D0.rodata.s.o(.rodata);
        build/asm/data/2422F0.rodata.s.o(.rodata);
        build/asm/data/242300.rodata.s.o(.rodata);
        build/asm/data/242310.rodata.s.o(.rodata);
        build/asm/data/242320.rodata.s.o(.rodata);
        build/asm/data/242330.rodata.s.o(.rodata);
        build/asm/data/242340.rodata.s.o(.rodata);
        build/asm/data/242350.rodata.s.o(.rodata);
        build/asm/data/242360.rodata.s.o(.rodata);
        build/asm/data/242370.rodata.s.o(.rodata);
        build/asm/data/242380.rodata.s.o(.rodata);
        build/asm/data/242390.rodata.s.o(.rodata);
        build/asm/data/2423A0.rodata.s.o(.rodata);
        build/asm/data/2423B0.rodata.s.o(.rodata);
        build/asm/data/2423C0.rodata.s.o(.rodata);
        build/asm/data/2423D0.rodata.s.o(.rodata);
        build/asm/data/2423E0.rodata.s.o(.rodata);
        build/asm/data/242420.rodata.s.o(.rodata);
        build/asm/data/242480.rodata.s.o(.rodata);
        build/asm/data/2424A0.rodata.s.o(.rodata);
        build/asm/data/2424E0.rodata.s.o(.rodata);
        build/asm/data/242740.rodata.s.o(.rodata);
        build/asm/data/242750.rodata.s.o(.rodata);
        build/asm/data/242960.rodata.s.o(.rodata);
        build/asm/data/242970.rodata.s.o(.rodata);
        build/asm/data/242F30.rodata.s.o(.rodata);
        build/asm/data/243B90.rodata.s.o(.rodata);
        build/asm/data/243DC0.rodata.s.o(.rodata);
        build/asm/data/243F60.rodata.s.o(.rodata);
        build/asm/data/244060.rodata.s.o(.rodata);
        build/asm/data/244140.rodata.s.o(.rodata);
        build/asm/data/244150.rodata.s.o(.rodata);
        build/asm/data/244160.rodata.s.o(.rodata);
        build/asm/data/244170.rodata.s.o(.rodata);
        build/asm/data/244180.rodata.s.o(.rodata);
        build/asm/data/244190.rodata.s.o(.rodata);
        build/asm/data/2441B0.rodata.s.o(.rodata);
        build/asm/data/2441D0.rodata.s.o(.rodata);
        build/asm/data/244210.rodata.s.o(.rodata);
        build/asm/data/244220.rodata.s.o(.rodata);
        build/asm/data/244250.rodata.s.o(.rodata);
        build/asm/data/2442D0.rodata.s.o(.rodata);
        build/asm/data/244360.rodata.s.o(.rodata);
        build/asm/data/244390.rodata.s.o(.rodata);
        build/asm/data/2443E0.rodata.s.o(.rodata);
        build/asm/data/244680.rodata.s.o(.rodata);
        build/asm/data/2446B0.rodata.s.o(.rodata);
        build/asm/data/2446E0.rodata.s.o(.rodata);
        build/asm/data/2446F0.rodata.s.o(.rodata);
        build/asm/data/2447B0.rodata.s.o(.rodata);
        build/asm/data/2447F0.rodata.s.o(.rodata);
        build/asm/data/244870.rodata.s.o(.rodata);
        build/asm/data/2448D0.rodata.s.o(.rodata);
        build/asm/data/244920.rodata.s.o(.rodata);
        build/asm/data/244930.rodata.s.o(.rodata);
        build/asm/data/244950.rodata.s.o(.rodata);
        build/asm/data/244A00.rodata.s.o(.rodata);
        build/asm/data/244A60.rodata.s.o(.rodata);
        build/asm/data/244A90.rodata.s.o(.rodata);
        build/asm/data/244AB0.rodata.s.o(.rodata);
        build/asm/data/244AC0.rodata.s.o(.rodata);
        build/asm/data/244AD0.rodata.s.o(.rodata);
        build/asm/data/244B70.rodata.s.o(.rodata);
        build/asm/data/244B80.rodata.s.o(.rodata);
        build/asm/data/244BC0.rodata.s.o(.rodata);
        build/asm/data/244C80.rodata.s.o(.rodata);
        build/asm/data/244C90.rodata.s.o(.rodata);
        build/asm/data/244CB0.rodata.s.o(.rodata);
        build/asm/data/244CD0.rodata.s.o(.rodata);
        build/asm/data/244D60.rodata.s.o(.rodata);
        build/asm/data/244DE0.rodata.s.o(.rodata);
        build/asm/data/244E00.rodata.s.o(.rodata);
        build/asm/data/244EB0.rodata.s.o(.rodata);
        build/asm/data/244EC0.rodata.s.o(.rodata);
        build/asm/data/244ED0.rodata.s.o(.rodata);
        build/asm/data/244F10.rodata.s.o(.rodata);
        build/asm/data/244F50.rodata.s.o(.rodata);
        build/asm/data/244F70.rodata.s.o(.rodata);
        build/asm/data/244F80.rodata.s.o(.rodata);
        build/asm/data/244F90.rodata.s.o(.rodata);
        build/asm/data/244FA0.rodata.s.o(.rodata);
        build/asm/data/244FB0.rodata.s.o(.rodata);
        build/asm/data/244FC0.rodata.s.o(.rodata);
        build/asm/data/2450A0.rodata.s.o(.rodata);
        build/asm/data/245100.rodata.s.o(.rodata);
        build/asm/data/2451C0.rodata.s.o(.rodata);
        build/asm/data/245270.rodata.s.o(.rodata);
        build/asm/data/2452B0.rodata.s.o(.rodata);
        build/asm/data/2452F0.rodata.s.o(.rodata);
        build/asm/data/245300.rodata.s.o(.rodata);
        build/asm/data/245320.rodata.s.o(.rodata);
        build/asm/data/245340.rodata.s.o(.rodata);
        build/asm/data/245350.rodata.s.o(.rodata);
        build/asm/data/245370.rodata.s.o(.rodata);
        build/asm/data/245380.rodata.s.o(.rodata);
        build/asm/data/245390.rodata.s.o(.rodata);
        build/asm/data/2453A0.rodata.s.o(.rodata);
        build/asm/data/2453B0.rodata.s.o(.rodata);
        build/asm/data/245480.rodata.s.o(.rodata);
        build/asm/data/2454F0.rodata.s.o(.rodata);
        build/asm/data/2455A0.rodata.s.o(.rodata);
        build/asm/data/2455B0.rodata.s.o(.rodata);
        build/asm/data/2455D0.rodata.s.o(.rodata);
        build/asm/data/2455F0.rodata.s.o(.rodata);
        build/asm/data/245600.rodata.s.o(.rodata);
        build/asm/data/2456C0.rodata.s.o(.rodata);
        build/asm/data/2457C0.rodata.s.o(.rodata);
        build/asm/data/245A20.rodata.s.o(.rodata);
        build/asm/data/245A30.rodata.s.o(.rodata);
        build/asm/data/245AA0.rodata.s.o(.rodata);
        build/asm/data/245AF0.rodata.s.o(.rodata);
        build/asm/data/245B20.rodata.s.o(.rodata);
        build/asm/data/245B30.rodata.s.o(.rodata);
        build/asm/data/245BD0.rodata.s.o(.rodata);
        build/asm/data/245C30.rodata.s.o(.rodata);
        build/asm/data/245C50.rodata.s.o(.rodata);
        build/asm/data/245C90.rodata.s.o(.rodata);
        build/asm/data/245EB0.rodata.s.o(.rodata);
        build/asm/data/245F20.rodata.s.o(.rodata);
        build/asm/data/245F30.rodata.s.o(.rodata);
        build/asm/data/245F40.rodata.s.o(.rodata);
        build/asm/data/245F50.rodata.s.o(.rodata);
        build/asm/data/245FC0.rodata.s.o(.rodata);
        build/asm/data/246030.rodata.s.o(.rodata);
        build/asm/data/2460B0.rodata.s.o(.rodata);
        build/asm/data/2460E0.rodata.s.o(.rodata);
        build/asm/data/246130.rodata.s.o(.rodata);
        build/asm/data/246140.rodata.s.o(.rodata);
        build/asm/data/246380.rodata.s.o(.rodata);
        build/asm/data/2463E0.rodata.s.o(.rodata);
        build/asm/data/246410.rodata.s.o(.rodata);
        build/asm/data/246440.rodata.s.o(.rodata);
        build/asm/data/2464A0.rodata.s.o(.rodata);
        build/asm/data/2464B0.rodata.s.o(.rodata);
        build/asm/data/246570.rodata.s.o(.rodata);
        build/asm/data/2465C0.rodata.s.o(.rodata);
        build/asm/data/2465F0.rodata.s.o(.rodata);
        build/asm/data/246640.rodata.s.o(.rodata);
        build/asm/data/246670.rodata.s.o(.rodata);
        build/asm/data/246680.rodata.s.o(.rodata);
        build/asm/data/2466C0.rodata.s.o(.rodata);
        build/asm/data/246780.rodata.s.o(.rodata);
        build/asm/data/246890.rodata.s.o(.rodata);
        build/asm/data/2469A0.rodata.s.o(.rodata);
        build/asm/data/246A30.rodata.s.o(.rodata);
        build/asm/data/246A70.rodata.s.o(.rodata);
        build/asm/data/246AC0.rodata.s.o(.rodata);
        build/asm/data/246B10.rodata.s.o(.rodata);
        build/asm/data/246BF0.rodata.s.o(.rodata);
        build/asm/data/246C60.rodata.s.o(.rodata);
        build/asm/data/246E10.rodata.s.o(.rodata);
        build/asm/data/246E30.rodata.s.o(.rodata);
        build/asm/data/246E40.rodata.s.o(.rodata);
        build/asm/data/246ED0.rodata.s.o(.rodata);
        build/asm/data/246EF0.rodata.s.o(.rodata);
        build/asm/data/246F10.rodata.s.o(.rodata);
        build/asm/data/246F30.rodata.s.o(.rodata);
        build/asm/data/246F70.rodata.s.o(.rodata);
        build/asm/data/246FE0.rodata.s.o(.rodata);
        build/asm/data/247160.rodata.s.o(.rodata);
        build/asm/data/247170.rodata.s.o(.rodata);
        build/asm/data/247180.rodata.s.o(.rodata);
        build/asm/data/2476E0.rodata.s.o(.rodata);
        build/asm/data/247780.rodata.s.o(.rodata);
        build/asm/data/247790.rodata.s.o(.rodata);
        build/asm/data/2477E0.rodata.s.o(.rodata);
        build/asm/data/247810.rodata.s.o(.rodata);
        build/asm/data/247860.rodata.s.o(.rodata);
        build/asm/data/247A10.rodata.s.o(.rodata);
        build/asm/data/247A20.rodata.s.o(.rodata);
        build/asm/data/247A30.rodata.s.o(.rodata);
        build/asm/data/247E40.rodata.s.o(.rodata);
        build/asm/data/247EE0.rodata.s.o(.rodata);
        build/asm/data/247EF0.rodata.s.o(.rodata);
        build/asm/data/247F00.rodata.s.o(.rodata);
        build/asm/data/247F20.rodata.s.o(.rodata);
        build/asm/data/247F30.rodata.s.o(.rodata);
        build/asm/data/247F60.rodata.s.o(.rodata);
        build/asm/data/game_14FF90.rodata.s.o(.rodata);
        build/asm/data/248070.rodata.s.o(.rodata);
        build/asm/data/2480D0.rodata.s.o(.rodata);
        build/asm/data/248160.rodata.s.o(.rodata);
        build/asm/data/2481A0.rodata.s.o(.rodata);
        build/asm/data/2481B0.rodata.s.o(.rodata);
        build/asm/data/2481E0.rodata.s.o(.rodata);
        build/asm/data/2481F0.rodata.s.o(.rodata);
        build/asm/data/248200.rodata.s.o(.rodata);
        build/asm/data/2482B0.rodata.s.o(.rodata);
        build/asm/data/248320.rodata.s.o(.rodata);
        build/asm/data/248340.rodata.s.o(.rodata);
        build/asm/data/2486F0.rodata.s.o(.rodata);
        build/asm/data/game_161520.rodata.s.o(.rodata);
        build/asm/data/249110.rodata.s.o(.rodata);
        build/asm/data/249480.rodata.s.o(.rodata);
        build/asm/data/249560.rodata.s.o(.rodata);
        build/asm/data/249CC0.rodata.s.o(.rodata);
        build/asm/data/249F40.rodata.s.o(.rodata);
        build/asm/data/24A190.rodata.s.o(.rodata);
        build/asm/data/24A220.rodata.s.o(.rodata);
        build/asm/data/24A230.rodata.s.o(.rodata);
        build/asm/data/24A240.rodata.s.o(.rodata);
        build/asm/data/24A360.rodata.s.o(.rodata);
        build/asm/data/24A400.rodata.s.o(.rodata);
        build/asm/data/24A920.rodata.s.o(.rodata);
        build/asm/data/24AAA0.rodata.s.o(.rodata);
        build/asm/data/24AAF0.rodata.s.o(.rodata);
        build/asm/data/24AB20.rodata.s.o(.rodata);
        build/asm/data/24AB30.rodata.s.o(.rodata);
        build/asm/data/24AB40.rodata.s.o(.rodata);
        build/asm/data/24AE60.rodata.s.o(.rodata);
        build/asm/data/24AF60.rodata.s.o(.rodata);
        build/asm/data/24AFF0.rodata.s.o(.rodata);
        build/asm/data/24B000.rodata.s.o(.rodata);
        build/asm/data/24B150.rodata.s.o(.rodata);
        build/asm/data/24B180.rodata.s.o(.rodata);
        build/asm/data/24B1F0.rodata.s.o(.rodata);
        build/asm/data/24B280.rodata.s.o(.rodata);
        build/asm/data/24B5E0.rodata.s.o(.rodata);
        build/asm/data/24B730.rodata.s.o(.rodata);
        build/asm/data/24B760.rodata.s.o(.rodata);
        build/asm/data/24B770.rodata.s.o(.rodata);
        build/asm/data/24B790.rodata.s.o(.rodata);
        build/asm/data/24B8C0.rodata.s.o(.rodata);
        build/asm/data/24B8F0.rodata.s.o(.rodata);
        build/asm/data/24B950.rodata.s.o(.rodata);
        build/asm/data/24BA40.rodata.s.o(.rodata);
        build/asm/data/24BA90.rodata.s.o(.rodata);
        build/asm/data/24BC20.rodata.s.o(.rodata);
        build/asm/data/24BC30.rodata.s.o(.rodata);
        build/asm/data/24BC80.rodata.s.o(.rodata);
        build/asm/data/24BCA0.rodata.s.o(.rodata);
        build/asm/data/24BCD0.rodata.s.o(.rodata);
        build/asm/data/24BCE0.rodata.s.o(.rodata);
        build/asm/data/24BCF0.rodata.s.o(.rodata);
        build/asm/data/24BD10.rodata.s.o(.rodata);
        build/asm/data/24BD90.rodata.s.o(.rodata);
        build/asm/data/24BE10.rodata.s.o(.rodata);
        build/asm/data/24BE50.rodata.s.o(.rodata);
        build/asm/data/24BE60.rodata.s.o(.rodata);
        build/asm/data/24BE80.rodata.s.o(.rodata);
        build/asm/data/24BE90.rodata.s.o(.rodata);
        build/asm/data/24BEC0.rodata.s.o(.rodata);
        build/asm/data/24BF10.rodata.s.o(.rodata);
        build/asm/data/24BF20.rodata.s.o(.rodata);
        build/asm/data/24CAD0.rodata.s.o(.rodata);
        build/asm/data/24CAF0.rodata.s.o(.rodata);
        build/asm/data/24CC40.rodata.s.o(.rodata);
        build/asm/data/24CC70.rodata.s.o(.rodata);
        build/asm/data/24CC80.rodata.s.o(.rodata);
        build/asm/data/24CCD0.rodata.s.o(.rodata);
        build/asm/data/24D1D0.rodata.s.o(.rodata);
        build/asm/data/24D640.rodata.s.o(.rodata);
        build/asm/data/24D7A0.rodata.s.o(.rodata);
        build/asm/data/24D7D0.rodata.s.o(.rodata);
        build/asm/data/24D7E0.rodata.s.o(.rodata);
        build/asm/data/24D810.rodata.s.o(.rodata);
        build/asm/data/24D830.rodata.s.o(.rodata);
        build/asm/data/24D840.rodata.s.o(.rodata);
        build/asm/data/24D880.rodata.s.o(.rodata);
        build/asm/data/24D8A0.rodata.s.o(.rodata);
        build/asm/data/24D8B0.rodata.s.o(.rodata);
        build/asm/data/24D960.rodata.s.o(.rodata);
        build/asm/data/24DA10.rodata.s.o(.rodata);
        build/asm/data/24DA30.rodata.s.o(.rodata);
        build/asm/data/24DAE0.rodata.s.o(.rodata);
        build/asm/data/24DD30.rodata.s.o(.rodata);
        build/asm/data/24DD60.rodata.s.o(.rodata);
        build/asm/data/24E830.rodata.s.o(.rodata);
        build/asm/data/24E840.rodata.s.o(.rodata);
        build/asm/data/24E8B0.rodata.s.o(.rodata);
        build/asm/data/24EBB0.rodata.s.o(.rodata);
        build/asm/data/24EBE0.rodata.s.o(.rodata);
        build/asm/data/24EDE0.rodata.s.o(.rodata);
        build/asm/data/24EE10.rodata.s.o(.rodata);
        build/asm/data/24EE40.rodata.s.o(.rodata);
        build/asm/data/24EE90.rodata.s.o(.rodata);
        build/asm/data/24EEC0.rodata.s.o(.rodata);
        build/asm/data/24EEF0.rodata.s.o(.rodata);
        build/asm/data/24EF10.rodata.s.o(.rodata);
        build/asm/data/24EF20.rodata.s.o(.rodata);
        build/asm/data/24EF50.rodata.s.o(.rodata);
        build/asm/data/24EFA0.rodata.s.o(.rodata);
        build/asm/data/24F040.rodata.s.o(.rodata);
        build/asm/data/24F050.rodata.s.o(.rodata);
        build/asm/data/24F370.rodata.s.o(.rodata);
        build/asm/data/24F3F0.rodata.s.o(.rodata);
        build/asm/data/24F490.rodata.s.o(.rodata);
        build/asm/data/24F550.rodata.s.o(.rodata);
        build/asm/data/24F5C0.rodata.s.o(.rodata);
        build/asm/data/24F6F0.rodata.s.o(.rodata);
        build/asm/data/24F740.rodata.s.o(.rodata);
        build/asm/data/24F9A0.rodata.s.o(.rodata);
        build/asm/data/24FB70.rodata.s.o(.rodata);
        build/asm/data/24FC00.rodata.s.o(.rodata);
        build/asm/data/24FD10.rodata.s.o(.rodata);
        build/asm/data/24FD40.rodata.s.o(.rodata);
        build/asm/data/24FDC0.rodata.s.o(.rodata);
        build/asm/data/24FDD0.rodata.s.o(.rodata);
        build/asm/data/24FE00.rodata.s.o(.rodata);
        build/asm/data/24FFC0.rodata.s.o(.rodata);
        build/asm/data/250010.rodata.s.o(.rodata);
        build/asm/data/250030.rodata.s.o(.rodata);
        build/asm/data/250550.rodata.s.o(.rodata);
        build/asm/data/2505E0.rodata.s.o(.rodata);
        build/asm/data/250730.rodata.s.o(.rodata);
        build/asm/data/2508E0.rodata.s.o(.rodata);
        build/asm/data/250B30.rodata.s.o(.rodata);
        build/asm/data/250F40.rodata.s.o(.rodata);
        build/asm/data/251950.rodata.s.o(.rodata);
        build/asm/data/252960.rodata.s.o(.rodata);
        build/asm/data/2531F0.rodata.s.o(.rodata);
        build/asm/data/255710.rodata.s.o(.rodata);
        . = ALIGN(., 16);
        game_data_RODATA_END = .;
        game_data_RODATA_SIZE = ABSOLUTE(game_data_RODATA_END - game_data_RODATA_START);
    }
    __romPos += SIZEOF(.game_data);
    __romPos = ALIGN(__romPos, 16);
    . = ALIGN(., 16);
    game_data_ROM_END = __romPos;
    game_data_VRAM_END = .;

    debugger_ROM_START = __romPos;
    debugger_VRAM = ADDR(.debugger);
    .debugger 0x16000000 : AT(debugger_ROM_START) SUBALIGN(16)
    {
        FILL(0x00000000);
        debugger_TEXT_START = .;
        build/src/debugger/debugger.c.o(.text);
        build/src/debugger_256F80.c.o(.text);
        build/src/debugger_257330.c.o(.text);
        build/src/debugger_257350.c.o(.text);
        build/src/debugger_258ED0.c.o(.text);
        . = ALIGN(., 8);
        debugger_TEXT_END = .;
        debugger_TEXT_SIZE = ABSOLUTE(debugger_TEXT_END - debugger_TEXT_START);
        debugger_RODATA_START = .;
        build/asm/data/258F70.rodata.s.o(.rodata);
        build/asm/data/259070.rodata.s.o(.rodata);
        build/asm/data/259370.rodata.s.o(.rodata);
        build/asm/data/2593B0.rodata.s.o(.rodata);
        build/asm/data/25A0F0.rodata.s.o(.rodata);
        . = ALIGN(., 8);
        debugger_RODATA_END = .;
        debugger_RODATA_SIZE = ABSOLUTE(debugger_RODATA_END - debugger_RODATA_START);
    }
    __romPos += SIZEOF(.debugger);
    __romPos = ALIGN(__romPos, 8);
    . = ALIGN(., 8);
    debugger_ROM_END = __romPos;
    debugger_VRAM_END = .;

    /DISCARD/ :
    {
        *(*);
    }
}
